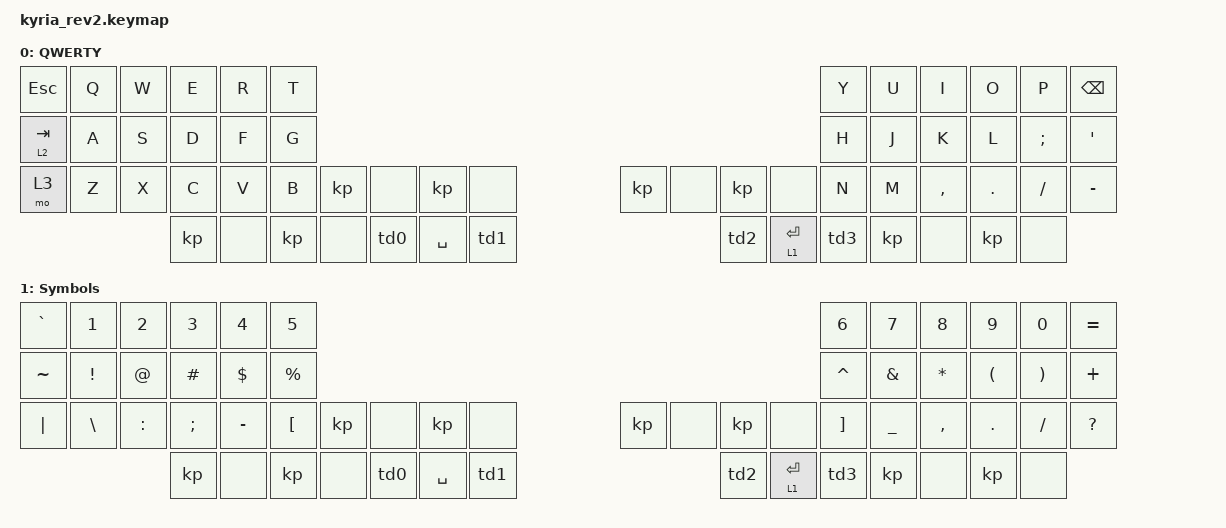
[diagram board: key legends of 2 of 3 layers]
/*
 * Copyright (c) 2020 The ZMK Contributors
 *
 * SPDX-License-Identifier: MIT
 */

#include <behaviors.dtsi>
#include <dt-bindings/zmk/keys.h>

/ {
    behaviors {
        td0: tap_dance_0 {
            compatible = "zmk,behavior-tap-dance";
            label = "TAP_DANCE_0";
            #binding-cells = <0>;
            tapping-term-ms = <200>;
            bindings = <&kp LSHIFT>, <&kp LALT>;
        };
        td1: tap_dance_1 {
            compatible = "zmk,behavior-tap-dance";
            label = "TAP_DANCE_1";
            #binding-cells = <0>;
            tapping-term-ms = <200>;
            bindings = <&kp LGUI>, <&kp LCTL>;
        };
        td2: tap_dance_2 {
            compatible = "zmk,behavior-tap-dance";
            label = "TAP_DANCE_2";
            #binding-cells = <0>;
            tapping-term-ms = <200>;
            bindings = <&kp LCTL>, <&kp LGUI>;
        };
        td3: tap_dance_3 {
            compatible = "zmk,behavior-tap-dance";
            label = "TAP_DANCE_3";
            #binding-cells = <0>;
            tapping-term-ms = <200>;
            bindings = <&kp RSHIFT>, <&kp RALT>;
        };
    };
  };

// Layers
#define QWERTY 0
#define Symbols 1
#define Navigation 2
#define F_keys_RGB 3

// None
#define ___ &none

/ {
    keymap {
        compatible = "zmk,keymap";

        default_layer {
          label = "QWERTY";
// ---------------------------------------------------------------------------------------------------------------------------------
// |  ESC  |  Q  |  W  |  E   |  R   |  T   |                                          |  Y   |  U    |  I    |  O   |   P   | Bspc |
// | TAB/L2|  A  |  S  |  D   |  F   |  G   |                                          |  H   |  J    |  K    |  L   |  ; :  | ' "  |
// |  L3   |  Z  |  X  |  C   |  V   |  B   |   ---   | ---   |         |  ---  |  --- |  N   |  M    |  , <  |  . > |  / ?  | - _  |
//                     | ---  | ---  | LShft/ | SPACE | LGUI/ |         |  LCTL/   |  Enter/ | RShft/ | ---   |  --- |
//                                   |  LALT  |       | LCTL  |         |  LGUI    |   L1    |  RALT
            bindings = <
    &kp ESC   &kp Q &kp W &kp E &kp R &kp T                                           &kp Y &kp U  &kp I     &kp O   &kp P    &kp BSPC
    &lt 2 TAB &kp A &kp S &kp D &kp F &kp G                                           &kp H &kp J  &kp K     &kp L   &kp SEMI &kp SQT
    &mo 3 &kp Z &kp X &kp C &kp V &kp B &kp ___ &kp ___               &kp ___ &kp ___ &kp N &kp M  &kp COMMA &kp DOT &kp FSLH &kp MINUS
                    &kp ___ &kp ___ &td0 &kp SPACE &td1               &td2 &lt 1 RET  &td3 &kp ___ &kp ___
            >;
            sensor-bindings = <&inc_dec_kp C_VOL_UP C_VOL_DN &inc_dec_kp PG_UP PG_DN>;
        };

        symbols_layer {
          label = "Symbols";
// ---------------------------------------------------------------------------------------------------------------------------------
// |  `  |  1  |  2  |  3   |  4   |  5   |                                           |   6   |   7   |   8   |   9  |  0  |  =  |
// | ~   |  !  |  @  |  #   |  $   |  %   |                                           |   ^   |   &   |   *   |   (  |  )  |  +  |
// | "|" |  \  |  :  |  ;   |  -   |  [   |   ---   | ---   |          |  ---  |  --- |   ]   |   _   |   ,   |   .  |  /  |  ?  |
//                   | ---  | ---  | LShft/ | SPACE | LGUI/ |          | LCTL/ | ENT/ | RShft/ | ---  |  ---  |
//                                 |  LALT  |       | LCTL  |          | LGUI  |  L1  |  RALT
            bindings = <
    &kp GRAVE &kp N1 &kp N2 &kp N3 &kp N4 &kp N5                                     &kp N6 &kp N7 &kp N8 &kp N9 &kp N0 &kp EQUAL
    &kp TILDE &kp EXCL &kp AT &kp HASH &kp DLLR &kp PRCNT                            &kp CARET &kp AMPS &kp STAR &kp LPAR &kp RPAR &kp PLUS
    &kp PIPE &kp BSLH &kp COLON &kp SEMI &kp MINUS &kp LBKT &kp ___ &kp ___               &kp ___ &kp ___ &kp RBKT &kp UNDER &kp COMMA &kp DOT &kp FSLH &kp QMARK
                    &kp ___ &kp ___ &td0 &kp SPACE &td1               &td2 &lt 1 RET  &td3 &kp ___ &kp ___
            >;
            sensor-bindings = <&inc_dec_kp C_VOL_UP C_VOL_DN &inc_dec_kp PG_UP PG_DN>;
        };

          navigation_layer {
            label = "Nav";
// ---------------------------------------------------------------------------------------------------------------------------------
// | RESET | --- | --- | ---  | scrnsht | --- |                                           | PgUp | Home |  ↑  | End | VolUp | Delete |
// | ---   | GUI | ALT | Ctrl | Shift   | --- |                                           | PgDn |  ←   |  ↓  | →   | VolDn | Insert |
// | ---   | --- | --- | ---  | ---     | --- | --- | ---   |          |  ---  |  --- |  Pause | M Prev | --- | M Next | VolMut | PrtSc |
//                   | ---  | ---  | LShft/ | SPACE | LGUI/ |          | LCTL/ | ENT/ | RShft/ | ---  |  ---  |
//                                 |  LALT  |       | LCTL  |          | LGUI  |  L1  |  RALT
            bindings = <
    &kp C_RESET &kp ___ &kp ___ &kp ___ &kp N4 &kp ___                                     &kp PG_UP &kp HOME &kp UP &kp END &kp K_VOL_UP &kp DEL
    &kp ___ &kp LGUI &kp LALT &kp LCTRL &kp LSHFT &kp ___                                  &kp PG_DN &kp LEFT &kp DOWN &kp RIGHT &kp K_VOL_DN &kp INS
    &kp ___ &kp ___ &kp ___ &kp ___ &kp ___ &kp ___ &kp ___ &kp ___   &kp ___ &kp ___ &kp C_PLAY_PAUSE &kp C_PREV &kp ___ &kp C_NEXT &kp C_MUTE &kp PSCRN
                    &kp ___ &kp ___ &td0 &kp SPACE &td1               &td2 &lt 1 RET  &td3 &kp ___ &kp ___
            >;
            sensor-bindings = <&inc_dec_kp C_VOL_UP C_VOL_DN &inc_dec_kp PG_UP PG_DN>;
        };
    };
};
